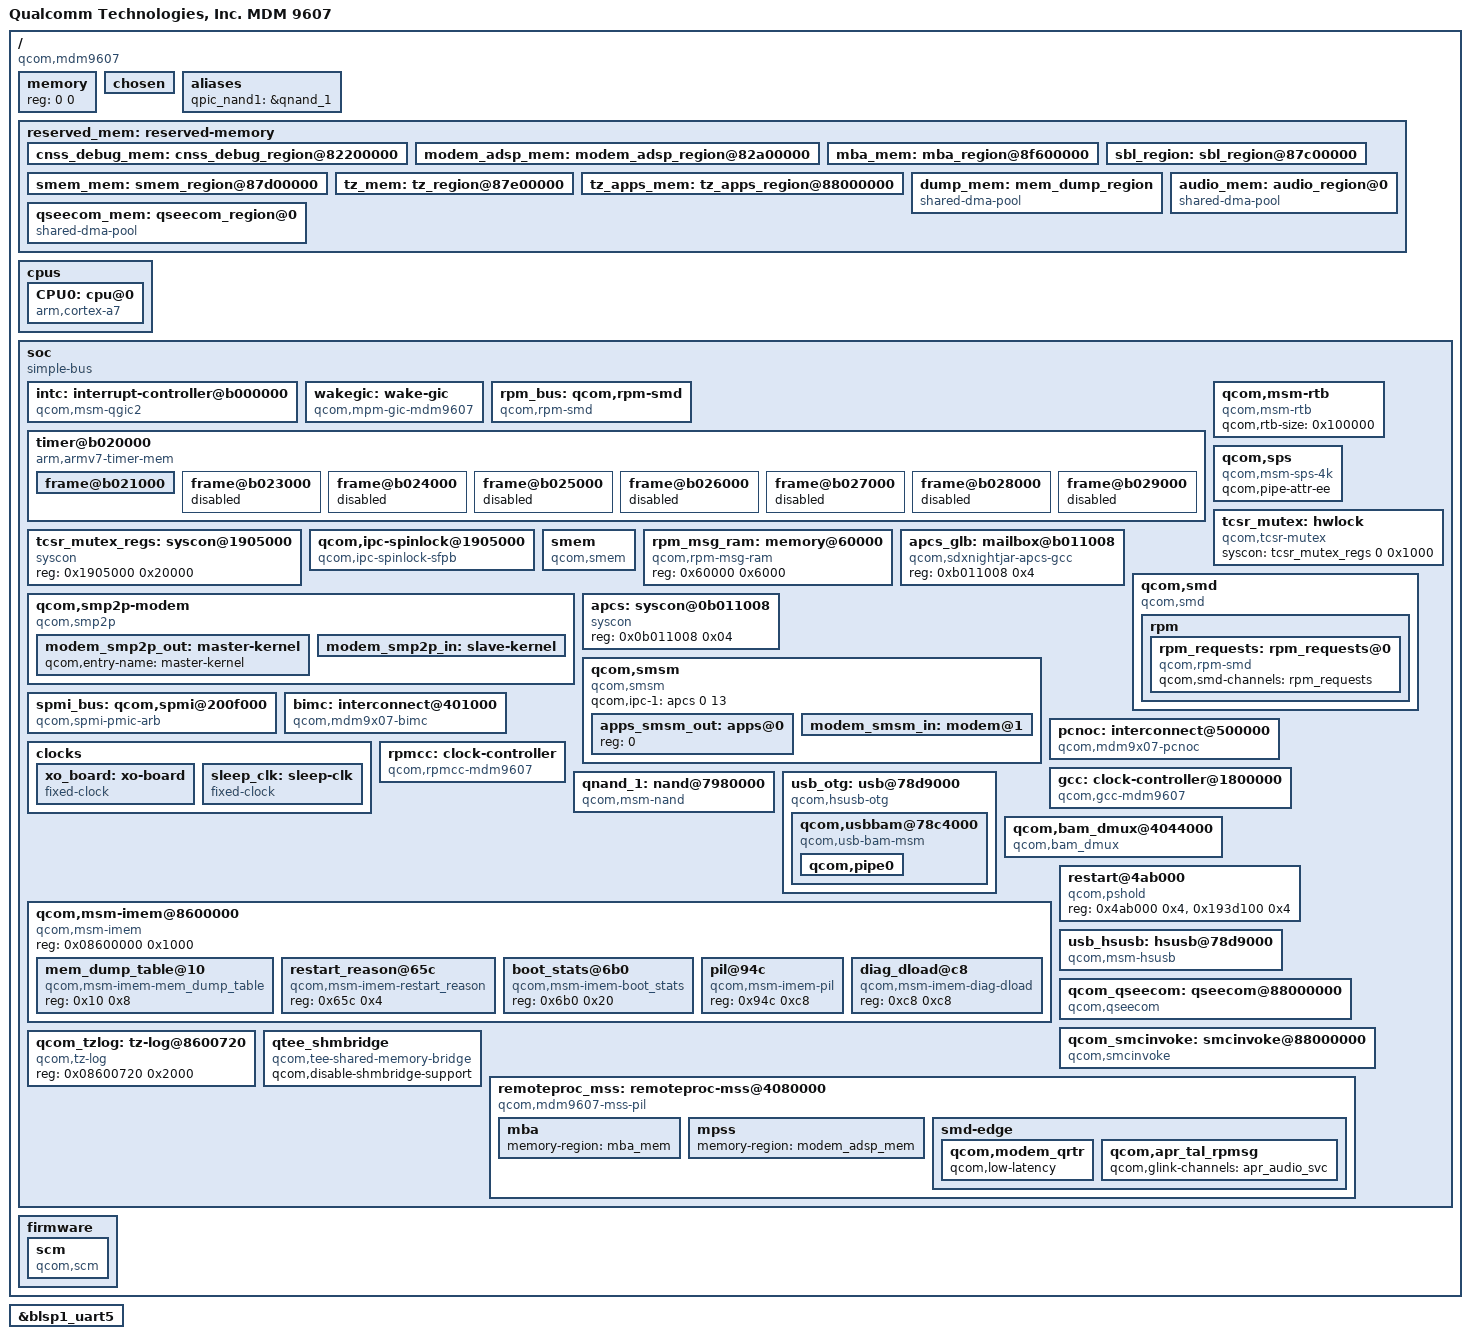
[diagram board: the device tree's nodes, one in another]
#include <dt-bindings/interrupt-controller/arm-gic.h>
#include <dt-bindings/regulator/qcom,rpm-smd-regulator.h>
#include <dt-bindings/spmi/spmi.h>
#include <dt-bindings/clock/qcom,gcc-mdm9607.h>
#include <dt-bindings/clock/qcom,rpmcc.h>
#include <dt-bindings/clock/qcom,rpmh.h>
#include <dt-bindings/interconnect/qcom,mdm9x07.h>
#include <dt-bindings/interconnect/qcom,icc.h>

#define MHZ_TO_MBPS(mhz, w) ((mhz * 1000000 * w) / (1024 * 1024))
#define BW_OPP_ENTRY(mhz, w) opp-mhz {opp-hz = /bits/ 64 <MHZ_TO_MBPS(mhz, w)>;}

/ {
	#address-cells = <1>;
	#size-cells = <1>;
	model = "Qualcomm Technologies, Inc. MDM 9607";
	compatible = "qcom,mdm9607";
	qcom,msm-id = <290 0x10000>, <296 0x10000>, <297 0x10000>,
		      <298 0x10000>, <299 0x10000>, <572 0x10000>;
	interrupt-parent = <&intc>;

	memory { device_type = "memory"; reg = <0 0>; };

	chosen: chosen { };

	aliases {
		qpic_nand1 = &qnand_1;
	};

	reserved_mem: reserved-memory {
		#address-cells = <1>;
		#size-cells = <1>;
		ranges;

		cnss_debug_mem: cnss_debug_region@82200000 {
			no-map;
			reg = <0x82200000 0x200000>;
			label = "cnss_debug_mem";
		};

		modem_adsp_mem: modem_adsp_region@82a00000 {
			no-map;
			reg = <0x82a00000 0x5000000>;
			label = "modem_adsp_mem";
		};

		mba_mem: mba_region@8f600000 {
			no-map;
			reg = <0x8f600000 0x100000>;
			label = "mba_mem";
		};

		sbl_region: sbl_region@87c00000 {
			no-map;
			reg = <0x87c00000 0x100000>;
			label = "sbl_mem";
		};

		smem_mem: smem_region@87d00000 {
			no-map;
			reg = <0x87d00000 0x100000>;
			label = "smem_mem";
		};

		tz_mem: tz_region@87e00000 {
			no-map;
			reg = <0x87e00000 0x200000>;
			label = "tz_mem";
		};

		tz_apps_mem: tz_apps_region@88000000 {
			no-map;
			reg = <0x88000000 0x500000>;
			label = "tz_apps_mem";
		};

		dump_mem: mem_dump_region {
			compatible = "shared-dma-pool";
			reusable;
			alignment = <0x400000>;
			size = <0x400000>;
		};

		audio_mem: audio_region@0 {
			compatible = "shared-dma-pool";
			reusable;
			alignment = <0x400000>;
			size = <0x400000>;
		};

		qseecom_mem: qseecom_region@0 {
			compatible = "shared-dma-pool";
			reusable;
			alignment = <0x400000>;
			size = <0x400000>;
			status = "ok";
		};
	};

	cpus {
		#size-cells = <0>;
		#address-cells = <1>;

		CPU0: cpu@0 {
			device_type = "cpu";
			compatible = "arm,cortex-a7";
			reg = <0x0>;
			enable-method = "psci";
			#cooling-cells = <2>;
		};
	};

	soc: soc { };

	firmware: firmware {};
};

&soc {
	#address-cells = <1>;
	#size-cells = <1>;
	ranges;
	compatible = "simple-bus";

	intc: interrupt-controller@b000000 {
		compatible = "qcom,msm-qgic2";
		interrupt-controller;
		interrupt-parent = <&intc>;
		#interrupt-cells = <3>;
		reg = <0x0b000000 0x1000>,
		      <0x0b002000 0x1000>;
	};

	wakegic: wake-gic {
		compatible = "qcom,mpm-gic-mdm9607", "qcom,mpm";
		interrupts = <GIC_SPI 197 IRQ_TYPE_EDGE_RISING>;
		reg = <0x601d0 0x1000>,
		      <0xb011008 0x4>,
		      <0xb021000 0x1000>;
		reg-names = "vmpm", "ipc", "timer";
		qcom,num-mpm-irqs = <64>;
		interrupt-controller;
		interrupt-parent = <&intc>;
		#interrupt-cells = <2>;
	};

	rpm_bus: qcom,rpm-smd {
		compatible = "qcom,rpm-smd";
		rpm-channel-name = "rpm_requests";
		interrupts = <GIC_SPI 168 IRQ_TYPE_EDGE_RISING>;
		rpm-channel-type = <15>; /* SMD_APPS_RPM */
	};

	timer@b020000 {
		#address-cells = <1>;
		#size-cells = <1>;
		ranges;
		compatible = "arm,armv7-timer-mem";
		reg = <0xb020000 0x1000>;
		clock-frequency = <19200000>;

		frame@b021000 {
			frame-number = <0>;
			interrupts = <0 7 0x4>,
				     <0 6 0x4>;
			reg = <0xb021000 0x1000>,
			      <0xb022000 0x1000>;
		};

		frame@b023000 {
			frame-number = <1>;
			interrupts = <0 8 0x4>;
			reg = <0xb023000 0x1000>;
			status = "disabled";
		};

		frame@b024000 {
			frame-number = <2>;
			interrupts = <0 9 0x4>;
			reg = <0xb024000 0x1000>;
			status = "disabled";
		};

		frame@b025000 {
			frame-number = <3>;
			interrupts = <0 10 0x4>;
			reg = <0xb025000 0x1000>;
			status = "disabled";
		};

		frame@b026000 {
			frame-number = <4>;
			interrupts = <0 11 0x4>;
			reg = <0xb026000 0x1000>;
			status = "disabled";
		};

		frame@b027000 {
			frame-number = <5>;
			interrupts = <0 12 0x4>;
			reg = <0xb027000 0x1000>;
			status = "disabled";
		};

		frame@b028000 {
			frame-number = <6>;
			interrupts = <0 13 0x4>;
			reg = <0xb028000 0x1000>;
			status = "disabled";
		};

		frame@b029000 {
			frame-number = <7>;
			interrupts = <0 14 0x4>;
			reg = <0xb029000 0x1000>;
			status = "disabled";
		};
	};

	qcom,msm-rtb {
		compatible = "qcom,msm-rtb";
		qcom,rtb-size = <0x100000>;
	};

	qcom,sps {
		compatible = "qcom,msm-sps-4k";
		qcom,pipe-attr-ee;
	};

	tcsr_mutex_regs: syscon@1905000 {
		compatible = "syscon";
		reg = <0x1905000 0x20000>;
	};

	tcsr_mutex: hwlock {
		compatible = "qcom,tcsr-mutex";
		syscon = <&tcsr_mutex_regs 0 0x1000>;
		#hwlock-cells = <1>;
	};

	qcom,ipc-spinlock@1905000 {
		compatible = "qcom,ipc-spinlock-sfpb";
		reg = <0x1905000 0x8000>;
		qcom,num-locks = <8>;
	};

	smem {
		compatible = "qcom,smem";
		memory-region = <&smem_mem>;
		qcom,rpm-msg-ram = <&rpm_msg_ram>;
		hwlocks = <&tcsr_mutex 3>;
	};

	rpm_msg_ram: memory@60000 {
		compatible = "qcom,rpm-msg-ram";
		reg = <0x60000 0x6000>;
	};

	apcs_glb: mailbox@b011008 {
		compatible = "qcom,sdxnightjar-apcs-gcc";
		reg = <0xb011008 0x4>;
		#mbox-cells = <1>;
	};

	qcom,smd {
		compatible = "qcom,smd";

		rpm {
			qcom,smd-edge = <15>;
			mboxes = <&apcs_glb 0>;
			interrupts = <GIC_SPI 168 IRQ_TYPE_EDGE_RISING>;
			label = "rpm";

			rpm_requests: rpm_requests@0 {
				compatible = "qcom,rpm-smd";
				qcom,smd-channels = "rpm_requests";
			};
		};
	};

	qcom,smp2p-modem {
		compatible = "qcom,smp2p";
		qcom,smem = <435>, <428>;
		interrupts = <GIC_SPI 27 IRQ_TYPE_EDGE_RISING>;
		mboxes = <&apcs_glb 14>;
		qcom,local-pid = <0>;
		qcom,remote-pid = <1>;

		modem_smp2p_out: master-kernel {
			qcom,entry-name = "master-kernel";
			#qcom,smem-state-cells = <1>;
		};

		modem_smp2p_in: slave-kernel {
			qcom,entry-name = "slave-kernel";
			interrupt-controller;
			#interrupt-cells = <2>;
		};
	};

	apcs: syscon@0b011008 {
		compatible = "syscon";
		reg = <0x0b011008 0x04>;
	};

	qcom,smsm {
		compatible = "qcom,smsm";

		#address-cells = <1>;
		#size-cells = <0>;

		qcom,ipc-1 = <&apcs 0 13>;

		apps_smsm_out: apps@0 {
			reg = <0>;
			#qcom,smem-state-cells = <1>;
		};

		modem_smsm_in: modem@1 {
			reg = <1>;
			interrupts = <GIC_SPI 26 IRQ_TYPE_EDGE_RISING>;

			interrupt-controller;
			#interrupt-cells = <2>;
		};
	};

	spmi_bus: qcom,spmi@200f000 {
		compatible = "qcom,spmi-pmic-arb";
		 reg = <0x200f000 0x1000>,
			<0x2400000 0x800000>,
			<0x2c00000 0x800000>,
			<0x3800000 0x200000>,
			<0x200a000 0x2100>;
		reg-names = "core", "chnls",
			"obsrvr", "intr", "cnfg";
		interrupt-names = "periph_irq";
		interrupts-extended = <&intc GIC_SPI 190 IRQ_TYPE_LEVEL_HIGH>;
		qcom,ee = <0>;
		qcom,channel = <0>;
		#address-cells = <1>;
		#size-cells = <0>;
		interrupt-controller;
		#interrupt-cells = <3>;
		cell-index = <0>;
	};

	bimc: interconnect@401000 {
		reg = <0x401000 0x58000>;
		compatible = "qcom,mdm9x07-bimc";
		qcom,keepalive;
		qcom,util-factor = <154>;
		#interconnect-cells = <1>;
		clock-names = "bus", "bus_a";
		clocks = <&rpmcc RPM_SMD_BIMC_CLK>,
			<&rpmcc RPM_SMD_BIMC_A_CLK>;
	};

	pcnoc: interconnect@500000 {
		reg = <0x500000 0x15080>;
		compatible = "qcom,mdm9x07-pcnoc";
		qcom,keepalive;
		#interconnect-cells = <1>;
		clock-names = "bus", "bus_a";
		clocks = <&rpmcc RPM_SMD_PCNOC_CLK>,
			<&rpmcc RPM_SMD_PCNOC_A_CLK>;
	};

	clocks {
		xo_board: xo-board {
			compatible = "fixed-clock";
			clock-frequency = <38400000>;
			clock-output-names = "xo_board";
			#clock-cells = <0>;
		};

		sleep_clk: sleep-clk {
			compatible = "fixed-clock";
			clock-frequency = <32000>;
			clock-output-names = "chip_sleep_clk";
			#clock-cells = <0>;
		};
	};

	rpmcc: clock-controller {
		compatible = "qcom,rpmcc-mdm9607";
		#clock-cells = <1>;
	};

	gcc: clock-controller@1800000 {
		compatible = "qcom,gcc-mdm9607", "syscon";
		reg = <0x1800000 0x80000>;
		reg-names = "cc_base";
		vdd_dig-supply = <&VDD_CX_LEVEL>;
		clocks = <&rpmcc RPM_SMD_XO_CLK_SRC>,
			 <&sleep_clk>;
		clock-names = "xo", "sleep_clk";
		#clock-cells = <1>;
		#reset-cells = <1>;
	};

	qnand_1: nand@7980000 {
		compatible = "qcom,msm-nand";
		reg = <0x07980000 0x1000>,
			<0x07984000 0x1a000>;
		reg-names = "nand_phys",
				"bam_phys";
		qcom,reg-adjustment-offset = <0x4000>;

		interrupts = <GIC_SPI 132 IRQ_TYPE_LEVEL_HIGH>;
		interrupt-names = "bam_irq";

		qcom,msm-bus,name = "qpic_nand";
		qcom,msm-bus,num-cases = <2>;
		qcom,msm-bus,num-paths = <1>;

		qcom,msm-bus,vectors-KBps =
			<0 0>,
		/* Voting for max b/w on PNOC bus for now */
			<400000 400000>;

		clock-names = "core_clk";
		clocks = <&rpmcc RPM_SMD_QPIC_CLK>;
		status = "ok";
	};

	usb_otg: usb@78d9000 {
		compatible = "qcom,hsusb-otg";
		reg = <0x78d9000 0x400>, <0x6c000 0x200>;
		reg-names = "core", "phy_csr";
		#address-cells = <1>;
		#size-cells = <1>;
		ranges;

		interrupts = <GIC_SPI 134 IRQ_TYPE_LEVEL_HIGH>,
			<GIC_SPI 140 IRQ_TYPE_LEVEL_HIGH>;
		interrupt-names = "core_irq", "async_irq";

		hsusb_vdd_dig-supply = <&mdm9607_l9>;
		HSUSB_1p8-supply = <&mdm9607_l2>;
		HSUSB_3p3-supply = <&mdm9607_l4>;
		qcom,vdd-voltage-level = <0 1225000 1225000>;

		qcom,hsusb-otg-phy-init-seq =
			<0x44 0x80 0x38 0x81 0x24 0x82 0x13 0x83 0xffffffff>;

		qcom,hsusb-otg-phy-type = <3>; /* SNPS Femto PHY */
		qcom,hsusb-otg-mode = <3>; /* OTG mode */
		qcom,hsusb-otg-otg-control = <2>; /* PMIC control */
		qcom,usbid-gpio = <&pm8019_mpps 1 0>;
		pinctrl-names = "default";
		pinctrl-0 = <&usb_id_default>;
		qcom,hsusb-log2-itc = <4>;
		qcom,dp-manual-pullup;
		qcom,boost-sysclk-with-streaming;
		qcom,phy-dvdd-always-on;
		qcom,hsusb-otg-lpm-on-dev-suspend;
		qcom,axi-prefetch-enable;
		qcom,hsusb-otg-mpm-dpsehv-int = <49>;
		qcom,hsusb-otg-mpm-dmsehv-int = <58>;
		qcom,hsusb-otg-delay-lpm;
		qcom,enable-phy-id-pullup;

		interconnect-names = "usb-ddr";
		interconnects = <&bimc MASTER_AMPSS_M0 &bimc SLAVE_EBI_CH0>;

		clocks = <&gcc GCC_USB_HS_AHB_CLK>,
			 <&gcc GCC_USB_HS_SYSTEM_CLK>,
			 <&gcc GCC_USB2A_PHY_SLEEP_CLK>,
			 <&gcc RPM_SMD_PCNOC_CLK>,
			 <&gcc RPM_SMD_PCNOC_A_CLK>,
			 <&gcc GCC_QUSB2_PHY_CLK>,
			 <&gcc GCC_USB2_HS_PHY_ONLY_CLK>,
			 <&gcc GCC_USB_HS_PHY_CFG_AHB_CLK>,
			 <&gcc RPM_SMD_XO_CLK_SRC>;
		clock-names =
			"iface_clk",
			"core_clk",
			"sleep_clk",
			"bimc_clk",
			"pcnoc_clk",
			"phy_reset_clk",
			"phy_por_clk",
			"phy_csr_clk",
			"xo";
		qcom,bus-clk-rate = <240000000 0 100000000
				     120000000 0  50000000>;
		qcom,max-nominal-sysclk-rate = <133330000>;
		qcom,max-svs-sysclk-rate = <69500000>;
		qcom,default-mode-svs;
		resets = <&gcc USB_HS_BCR>,
			<&gcc QUSB2_PHY_BCR>,
			<&gcc USB2_HS_PHY_ONLY_BCR>;
		reset-names = "core_reset", "phy_reset", "phy_por_reset";

		qcom,usbbam@78c4000 {
			compatible = "qcom,usb-bam-msm";
			reg = <0x78c4000 0x15000>;
			interrupt-parent = <&intc>;
			interrupts = <0 135 IRQ_TYPE_LEVEL_HIGH>;
			qcom,bam-type = <1>;
			qcom,usb-bam-num-pipes = <2>;
			qcom,usb-bam-fifo-baseaddr = <0x08603800>;
			qcom,ignore-core-reset-ack;
			qcom,disable-clk-gating;
			qcom,reset-bam-on-disconnect;

			qcom,pipe0 {
				label = "hsusb-qdss-in-0";
				qcom,usb-bam-mem-type = <2>;
				qcom,dir = <1>;
				qcom,pipe-num = <0>;
				qcom,peer-bam = <0>;
				qcom,peer-bam-physical-address = <0x6084000>;
				qcom,src-bam-pipe-index = <0>;
				qcom,dst-bam-pipe-index = <0>;
				qcom,data-fifo-offset = <0x0>;
				qcom,data-fifo-size = <0x600>;
				qcom,descriptor-fifo-offset = <0x600>;
				qcom,descriptor-fifo-size = <0x200>;
			};
		};
	};

	qcom,bam_dmux@4044000 {
		compatible = "qcom,bam_dmux";
		reg = <0x4044000 0x19000>;
		qcom,rx-ring-size = <32>;
		qcom,max-rx-mtu = <4096>;
		qcom,fast-shutdown;
		qcom,smem-states = <&apps_smsm_out 1>, <&apps_smsm_out 11>;
		qcom,smem-state-names = "pwrctrl", "pwrctrlack";
		interrupts-extended =
				<&intc GIC_SPI 29 IRQ_TYPE_EDGE_RISING>,
				<&modem_smsm_in 1 IRQ_TYPE_EDGE_BOTH>,
				<&modem_smsm_in 11 IRQ_TYPE_EDGE_BOTH>;
		interrupt-names = "dmux", "ctrl", "ack";
	};

	qcom,msm-imem@8600000 {
		compatible = "qcom,msm-imem";
		reg = <0x08600000 0x1000>; /* Address and size of IMEM */
		ranges = <0x0 0x08600000 0x1000>;
		#address-cells = <1>;
		#size-cells = <1>;

		mem_dump_table@10 {
			compatible = "qcom,msm-imem-mem_dump_table";
			reg = <0x10 0x8>;
		};

		restart_reason@65c {
			compatible = "qcom,msm-imem-restart_reason";
			reg = <0x65c 0x4>;
		};

		boot_stats@6b0 {
			compatible = "qcom,msm-imem-boot_stats";
			reg = <0x6b0 0x20>;
		};

		pil@94c {
			compatible = "qcom,msm-imem-pil";
			reg = <0x94c 0xc8>;
		};

		diag_dload@c8 {
			compatible = "qcom,msm-imem-diag-dload";
			reg = <0xc8 0xc8>;
		};
	};

	restart@4ab000 {
		compatible = "qcom,pshold";
		reg = <0x4ab000 0x4>,
		    <0x193d100 0x4>;
		reg-names = "pshold-base", "tcsr-boot-misc-detect";
	};

	usb_hsusb: hsusb@78d9000 {
		compatible = "qcom,msm-hsusb";
		reg = <0x78d9000 0x400>;
		reg-names = "core";
		#address-cells = <1>;
		#size-cells = <1>;
		ranges;

		interrupts = <GIC_SPI 134 IRQ_TYPE_LEVEL_HIGH>;

		hsusb_vdd_dig-supply = <&mdm9607_l9>;
		HSUSB_1p8-supply = <&mdm9607_l2>;
		HSUSB_3p3-supply = <&mdm9607_l4>;
		qcom,usbid-gpio = <&pm8019_mpps 1 0>;
		pinctrl-0 = <&usb_id_default>;
	};

	qcom_qseecom: qseecom@88000000 {
		compatible = "qcom,qseecom";
		reg = <0x88000000 0x500000>;
		reg-names = "secapp-region";
		memory-region = <&qseecom_mem>;
		qcom,hlos-ce-hw-instance = <0>;
		qcom,qsee-ce-hw-instance = <0>;
		qcom,msm-bus,name = "qseecom-noc";
		qcom,msm-bus,num-cases = <4>;
		qcom,msm-bus,num-paths = <1>;
		qcom,support-bus-scaling;
		qcom,msm-bus,vectors-KBps =
				<47 512 0 0>,
				<47 512 0 0>,
				<47 512 120000 1200000>,
				<47 512 393600 3936000>;
		clocks = <&gcc CRYPTO_CLK_SRC>,
			<&gcc GCC_CRYPTO_CLK>,
			<&gcc GCC_CRYPTO_AHB_CLK>,
			<&gcc GCC_CRYPTO_AXI_CLK>;
		clock-names = "core_clk_src", "core_clk",
				"iface_clk", "bus_clk";
		qcom,ce-opp-freq = <100000000>;
		status = "ok";
	};

	qcom_smcinvoke: smcinvoke@88000000 {
		compatible = "qcom,smcinvoke";
		reg = <0x88000000 0x500000>;
		qcom,support-legacy_smc;
		qcom,clock-support;
		status = "ok";
	};

	qcom_tzlog: tz-log@8600720 {
		compatible = "qcom,tz-log";
		reg = <0x08600720 0x2000>;
		status = "ok";
	};

	qtee_shmbridge {
		compatible = "qcom,tee-shared-memory-bridge";
		qcom,disable-shmbridge-support;
	};

	remoteproc_mss: remoteproc-mss@4080000 {
		compatible = "qcom,mdm9607-mss-pil";
		reg = <0x04080000 0x100>,
			<0x0194f000 0x010>,
			<0x01950000 0x008>,
			<0x01951000 0x008>,
			<0x04020000 0x040>,
			<0x0183e000 0x004>;
		reg-names = "qdsp6", "halt_q6", "halt_modem", "halt_nc",
			"rmb", "restart_reg";

		interrupts-extended = <&intc GIC_SPI 24 IRQ_TYPE_EDGE_RISING>,
			<&modem_smp2p_in 0 IRQ_TYPE_EDGE_RISING>,
			<&modem_smp2p_in 2 IRQ_TYPE_EDGE_RISING>,
			<&modem_smp2p_in 1 IRQ_TYPE_EDGE_RISING>,
			<&modem_smp2p_in 3 IRQ_TYPE_EDGE_RISING>,
			<&modem_smp2p_in 7 IRQ_TYPE_EDGE_RISING>;
		interrupt-names = "wdog", "fatal", "ready",
						  "handover", "stop-ack",
						  "shutdown-ack";
		clocks = <&rpmcc RPM_SMD_XO_CLK_SRC>,
			<&gcc GCC_MSS_CFG_AHB_CLK>,
			<&gcc GCC_MSS_Q6_BIMC_AXI_CLK >,
			<&gcc GCC_BOOT_ROM_AHB_CLK>;
			clock-names = "xo", "iface", "bus", "mem";
			qcom,proxy-clock-names = "xo";
			qcom,active-clock-names = "iface", "bus", "mem";

		qcom,smem-states = <&modem_smp2p_out 0>;
		qcom,smem-state-names = "stop";

		resets = <&gcc GCC_MSS_RESTART>;
		reset-names = "mss_restart";

		qcom,halt-regs = <&tcsr_mutex_regs 0x3000 0x5000 0x4000>;

		cx-supply = <&mdm9607_s3_level>;
		cx-uV-uA = <RPM_SMD_REGULATOR_LEVEL_TURBO 0>;
		mx-supply = <&mdm9607_l12_level>;
		mx-uV-uA = <RPM_SMD_REGULATOR_LEVEL_TURBO 0>;
		pll-supply = <&mdm9607_l3>;
		pll-uV-uA = <1800000 0>;

		qcom,firmware-name = "mba.mbn", "modem.mdt";
		firmware-name = "mba.mbn", "modem.mdt";
		qcom,pil-self-auth;
		qcom,sysmon-id = <0>;
		qcom,ssctl-instance-id = <0x12>;
		qcom,override-acc-1 = <0x80800000>;
		qcom,qdsp6v56-1-8-inrush-current;
		qcom,reset-clk;
		qcom,sequential-fw-load;

		mba {
			memory-region = <&mba_mem>;
		};

		mpss {
			memory-region = <&modem_adsp_mem>;
		};

		smd-edge {
			qcom,smd-edge = <0>;
			mboxes = <&apcs_glb 12>;
			qcom,remote-pid = <1>;
			mbox-names = "mpss_smem";
			interrupts = <GIC_SPI 25 IRQ_TYPE_EDGE_RISING>;
			label = "mpss";

			qcom,smd-channels = "IPCRTR";
			qcom,modem_qrtr {
			qcom,low-latency;
			};

			qcom,apr_tal_rpmsg {
			qcom,glink-channels = "apr_audio_svc";
			};
		};
	};
};

#include "mdm9x07-pinctrl.dtsi"
#include "pm8019-rpm-regulator.dtsi"
#include "mdm9607-regulator.dtsi"
#include "mdm9607-blsp.dtsi"
#include "pm8019.dtsi"

&blsp1_uart5 {
	status = "ok";
};

&firmware {
	scm {
		compatible = "qcom,scm";
	};
};
